# M367 register map
File version: 0.1
CPU: 
Registers are 32-bit, read-write, reset 0x0 unless marked. A register's access mark holds for its fields unless they carry their own. Offsets are from the block's base; [hi:lo] are bit positions; {n}, {i} and the like mark numbered series.

## MT0 — 16-bit Multi-Purpose Timer (MPT-TMR_IGBT)
Base 0x400C7000
Same registers: MT1 0x400C7100, MT2 0x400C7200, MT3 0x400C7300
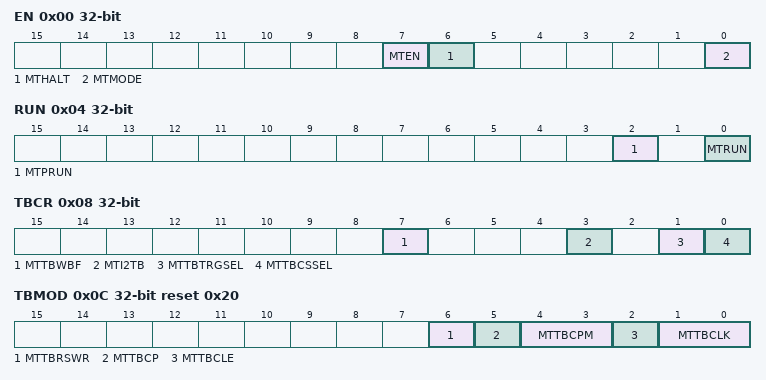
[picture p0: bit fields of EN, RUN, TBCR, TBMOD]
0x00 EN — MPT Enable Register
  [7] MTEN, [6] MTHALT, [0] MTMODE
0x04 RUN — MPT RUN Register
  [2] MTPRUN, [0] MTRUN
0x08 TBCR — MPT Control Register
  [7] MTTBWBF, [3] MTI2TB, [1] MTTBTRGSEL, [0] MTTBCSSEL
0x0C TBMOD reset 0x20 — MPT Mode Register
  [6] MTTBRSWR, [5] MTTBCP wo, [4:3] MTTBCPM, [2] MTTBCLE, [1:0] MTTBCLK
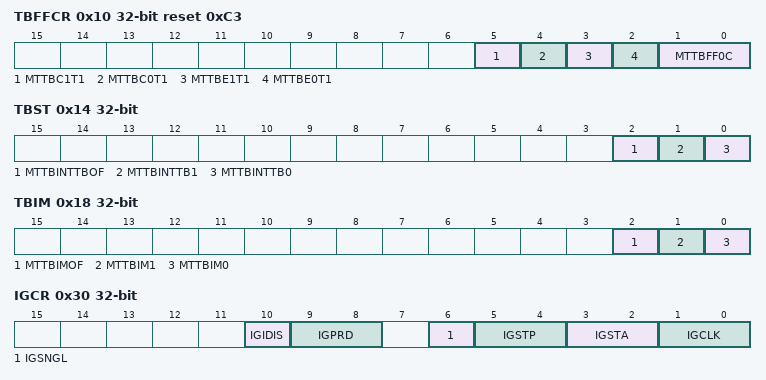
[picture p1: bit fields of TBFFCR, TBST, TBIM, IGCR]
0x10 TBFFCR reset 0xC3 — MPT Flip-Flop Control Register
  [5] MTTBC1T1, [4] MTTBC0T1, [3] MTTBE1T1, [2] MTTBE0T1, [1:0] MTTBFF0C
0x14 TBST ro — MPT Status Register
  [2] MTTBINTTBOF, [1] MTTBINTTB1, [0] MTTBINTTB0
0x18 TBIM — MPT Interrupt Mask Register
  [2] MTTBIMOF, [1] MTTBIM1, [0] MTTBIM0
0x1C TBUC ro — MPT Read Capture Register
  [15:0] MTUC
0x20 RG0 — MPT RG0 Timer Register
  [15:0] MTRG0
0x24 RG1 — MPT RG1 Timer Register
  [15:0] MTRG1
0x28 CP0 ro — MPT CP0 Capture Register
  [15:0] MTCP0
0x2C CP1 ro — MPT CP1 Capture Register
  [15:0] MTCP1
0x30 IGCR — IGBT Control Register
  [10] IGIDIS, [9:8] IGPRD, [6] IGSNGL, [5:4] IGSTP, [3:2] IGSTA, [1:0] IGCLK
0x34 IGRESTA wo — IGBT Timer Restart Register
  [0] IGRESTA
0x38 IGST ro — IGBT Timer Status Register
  [0] IGST
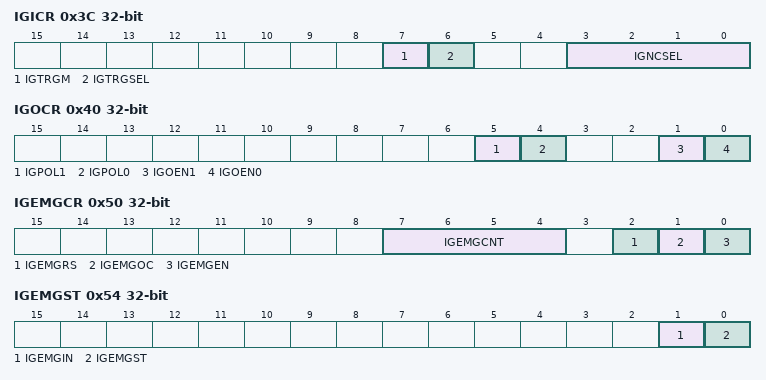
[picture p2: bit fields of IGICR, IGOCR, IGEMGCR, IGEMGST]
0x3C IGICR — IGBT Input Control Register
  [7] IGTRGM, [6] IGTRGSEL, [3:0] IGNCSEL
0x40 IGOCR — IGBT Output Control Register
  [5] IGPOL1, [4] IGPOL0, [1] IGOEN1, [0] IGOEN0
{0x3C+4i} IGRG{i} (i=2..4) — IGBT RG{i} Timer Register
  [15:0] IGRG{i}
0x50 IGEMGCR — IGBT EMG Control Register
  [7:4] IGEMGCNT, [2] IGEMGRS wo, [1] IGEMGOC, [0] IGEMGEN
0x54 IGEMGST ro — IGBT EMG Status Register
  [1] IGEMGIN, [0] IGEMGST

## RTC — Real Time Clock (RTC)
Base 0x400CC000
0x00 SECR 8-bit (reset mask 0x80) — RTC Second Column Register
  [6:0] SE
0x01 MINR 8-bit (reset mask 0x80) — RTC Minute Column Register
  [6:0] MI
0x02 HOURR 8-bit (reset mask 0xC0) — RTC Hour Column Register
  [5:0] HO
0x04 DAYR 8-bit (reset mask 0xF8) — RTC Day of the Week Column Register
  [2:0] WE
0x05 DATER 8-bit (reset mask 0xC0) — RTC Day Column Register
  [5:0] DA
0x06 MONTHR_A 8-bit (reset mask 0xE0) — RTC Month Column Register
  [4:0] MO
0x06 MONTHR_B 8-bit (reset mask 0xFE) (RTC_MONTHR view) — RTC Month Column Register
  [0] MO0
0x07 YEARR_A 8-bit reset not defined — RTC Year Column Register
  [7:0] YE
0x07 YEARR_B 8-bit (reset mask 0xFC) (RTC_YEARR view) — RTC Year Column Register
  [1:0] LEAP
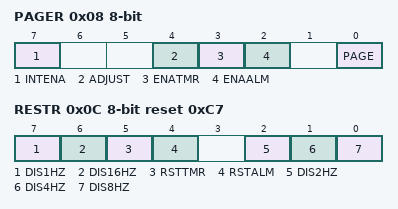
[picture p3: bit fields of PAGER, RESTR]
0x08 PAGER 8-bit (reset mask 0xF3) — RTC PAGE Register
  [7] INTENA, [4] ADJUST, [3] ENATMR, [2] ENAALM, [0] PAGE
0x0C RESTR 8-bit reset 0xC7 — RTC Reset Register
  [7] DIS1HZ, [6] DIS16HZ, [5] RSTTMR, [4] RSTALM, [2] DIS2HZ, [1] DIS4HZ, [0] DIS8HZ

## SBI0 — Serial Bus Interface (SBI)
Base 0x400E0000
Same registers: SBI1 0x400E0100, SBI2 0x400E0200
0x00 CR0 — SBI Control Register 0
  [7] SBIEN
0x04 CR1_A reset 0x3 — SBI Control Register 1 (I2C Mode)
  [7:5] BC, [4] ACK, [0] SWRMON ro, [2:0] SCK wo
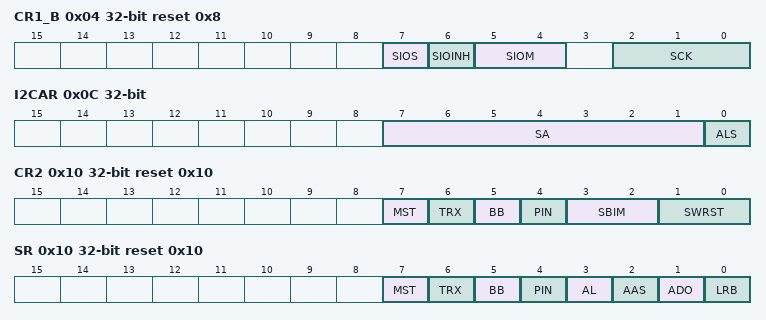
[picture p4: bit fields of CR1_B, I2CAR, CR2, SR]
0x04 CR1_B reset 0x8 (SBI_CR1 view) — SBI Control Register 1 (SIO Mode)
  [7] SIOS, [6] SIOINH, [5:4] SIOM, [2:0] SCK
0x08 DBR — SBI Data Buffer Register
  [7:0] DB
0x0C I2CAR — SBI I2C Bus Address Register
  [7:1] SA, [0] ALS
0x10 CR2 wo reset 0x10 — SBI Control Register 2 (I2C Mode)
  [7] MST, [6] TRX, [5] BB, [4] PIN, [3:2] SBIM, [1:0] SWRST
0x10 SR ro reset 0x10 — SBI Status Register (I2C Mode)
  [7] MST, [6] TRX, [5] BB, [4] PIN, [3] AL, [2] AAS, [1] ADO, [0] LRB
0x14 BR0 reset 0xBE — SBI Baud Rate Register 0
  [6] I2SBI

## SC0 — Serial Channel (SC)
Base 0x400E1000
Same registers: SC1 0x400E1100, SC2 0x400E1200, SC3 0x400E1300
0x00 EN — SC Enable Register
  [0] SIOE
0x04 BUF — SC Buffer Register
  [7:0] TB_RB
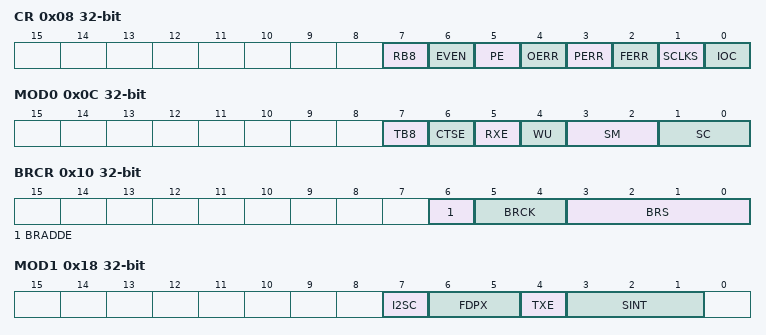
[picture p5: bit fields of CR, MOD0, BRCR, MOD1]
0x08 CR — SC Control Register
  [7] RB8 ro, [6] EVEN, [5] PE, [4] OERR ro, [3] PERR ro, [2] FERR ro, [1] SCLKS, [0] IOC
0x0C MOD0 — SC Mode Control Register 0
  [7] TB8, [6] CTSE, [5] RXE, [4] WU, [3:2] SM, [1:0] SC
0x10 BRCR — SC Baud Rate Generator Control Register
  [6] BRADDE, [5:4] BRCK, [3:0] BRS
0x14 BRADD — SC Baud Rate Generator Control Register 2
  [3:0] BRK
0x18 MOD1 — SC Mode Control Register 1
  [7] I2SC, [6:5] FDPX, [4] TXE, [3:1] SINT
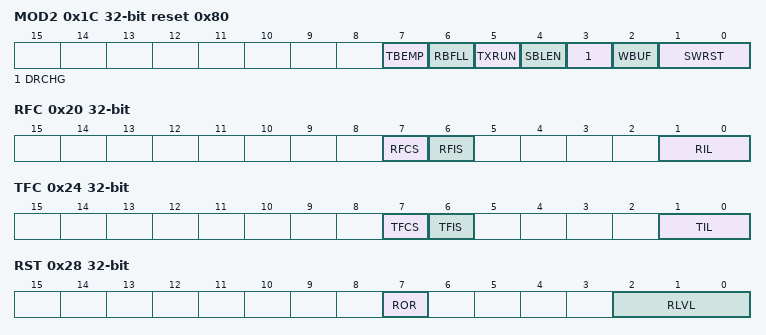
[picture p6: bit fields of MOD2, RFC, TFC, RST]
0x1C MOD2 reset 0x80 — SC Mode Control Register 2
  [7] TBEMP ro, [6] RBFLL ro, [5] TXRUN ro, [4] SBLEN, [3] DRCHG, [2] WBUF, [1:0] SWRST
0x20 RFC — SC RX FIFO Configuration Register
  [7] RFCS wo, [6] RFIS, [1:0] RIL
0x24 TFC — SC TX FIFO Configuration Register
  [7] TFCS wo, [6] TFIS, [1:0] TIL
0x28 RST ro — SC RX FIFO Status Register
  [7] ROR, [2:0] RLVL
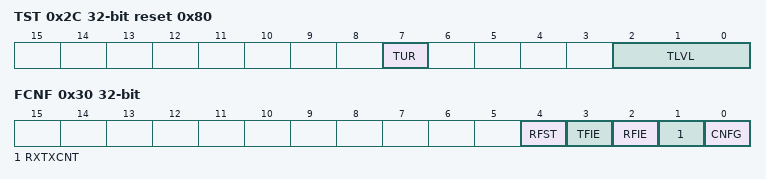
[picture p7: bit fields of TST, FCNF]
0x2C TST ro reset 0x80 — SC TX FIFO Status Register
  [7] TUR, [2:0] TLVL
0x30 FCNF — SC FIFO Configuration Register
  [4] RFST, [3] TFIE, [2] RFIE, [1] RXTXCNT, [0] CNFG
